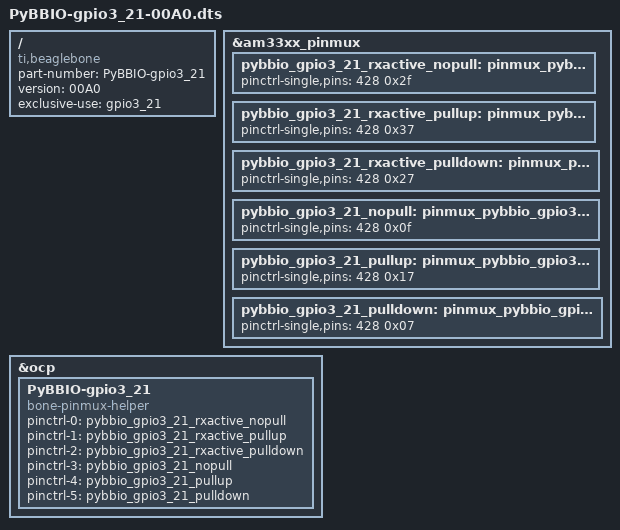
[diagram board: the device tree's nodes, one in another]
/dts-v1/;
/plugin/;

/{
  compatible = "ti,beaglebone", "ti,beaglebone-black";

  part-number = "PyBBIO-gpio3_21";
  version = "00A0";

  /* state the resources this cape uses */
  exclusive-use =
    /* the pin header uses */

    /* the hardware IP uses */
    "gpio3_21";

  fragment@0 {
    target = <&am33xx_pinmux>;
    __overlay__ {

      pybbio_gpio3_21_rxactive_nopull: pinmux_pybbio_gpio3_21_rxactive_nopull {
        pinctrl-single,pins = <
          428 0x2f  /* mcasp0_ahclkx - rx active | no pull | MODE7 (gpio3_21) */
        >;
      };
      pybbio_gpio3_21_rxactive_pullup: pinmux_pybbio_gpio3_21_rxactive_pullup {
        pinctrl-single,pins = <
          428 0x37  /* mcasp0_ahclkx - rx active | pull up | MODE7 (gpio3_21) */
        >;
      };
      pybbio_gpio3_21_rxactive_pulldown: pinmux_pybbio_gpio3_21_rxactive_pulldown {
        pinctrl-single,pins = <
          428 0x27  /* mcasp0_ahclkx - rx active | pull down | MODE7 (gpio3_21) */
        >;
      };
      
      pybbio_gpio3_21_nopull: pinmux_pybbio_gpio3_21_nopull {
        pinctrl-single,pins = <
          428 0x0f  /* mcasp0_ahclkx - rx active | no pull | MODE7 (gpio3_21) */
        >;
      };
      pybbio_gpio3_21_pullup: pinmux_pybbio_gpio3_21_pullup {
        pinctrl-single,pins = <
          428 0x17  /* mcasp0_ahclkx - rx active | pull up | MODE7 (gpio3_21) */
        >;
      };
      pybbio_gpio3_21_pulldown: pinmux_pybbio_gpio3_21_pulldown {
        pinctrl-single,pins = <
          428 0x07  /* mcasp0_ahclkx - rx active | pull down | MODE7 (gpio3_21) */
        >;
      };
      
    };
  };

  fragment@1 {
    target = <&ocp>; /* On-Chip Peripherals */
    __overlay__ {
      PyBBIO-gpio3_21 {
        compatible = "bone-pinmux-helper"; /* Use the pinmux helper */
        status="okay";
        /* Define custom names for indexes in pinctrl array: */ 
        pinctrl-names = "mode_0b00101111", "mode_0b00110111", "mode_0b00100111",
                        "mode_0b00001111", "mode_0b00010111", "mode_0b00000111";
        /* Set the elements of the pinctrl array to the pinmux overlays
           defined above: */
        pinctrl-0 = <&pybbio_gpio3_21_rxactive_nopull>; 
        pinctrl-1 = <&pybbio_gpio3_21_rxactive_pullup>; 
        pinctrl-2 = <&pybbio_gpio3_21_rxactive_pulldown>;
        pinctrl-3 = <&pybbio_gpio3_21_nopull>; 
        pinctrl-4 = <&pybbio_gpio3_21_pullup>; 
        pinctrl-5 = <&pybbio_gpio3_21_pulldown>;
      };
    };
  };
};
